# PIC32CX0525SG12084 register map
Vendor: Microchip Technology; Series: 0525SG12; File version: 0
CPU: CM4 r1p0, little endian, no MPU, no FPU, 3 interrupt priority bits, 172 interrupts
Registers are 32-bit, read-write, reset 0x0 unless marked. A register's access mark holds for its fields unless they carry their own. Offsets are from the block's base; [hi:lo] are bit positions.

## I2C0 — The I2C interface can handle standard I2C interface.
Base 0x40005100; register names take the prefix I2C_
Same registers: I2C1 0x40005200, I2C2 0x40005300
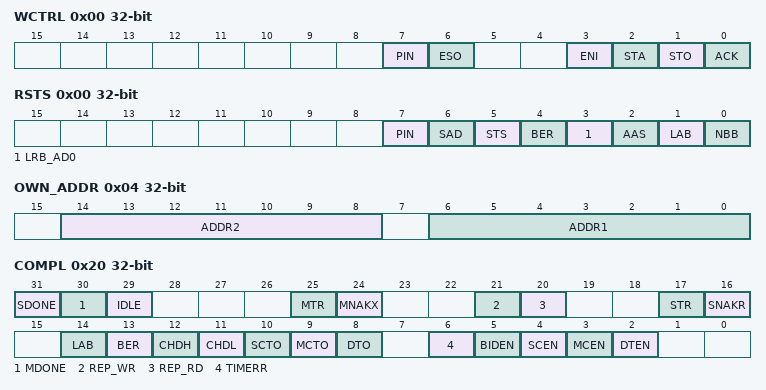
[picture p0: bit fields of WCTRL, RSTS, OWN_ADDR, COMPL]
0x00 WCTRL wo — Control Register
  [7] PIN — The Pending Interrupt Not (PIN) bit serves as a software reset function. Writing the PIN bit to a logic '1' de-asserts all status bits except for the nBB bit which is not affected by the PIN bit. The PIN bit is a self-clearing bit. Writing this bit to a logic '0' has no effect.
  [6] ESO — The Enable Serial Output bit (ESO) enables and disables the SMB Controller Core serial data output (SDAT)
  [3] ENI — Enable Interrupt bit (ENI) controls the Interrupt Interface
  [2] STA — The STA and STO bits control the generation of the I2C Start condition and the transmission of the Slave Address and R/nW bit (from the Data Register), generation of repeated Start condition, and generation of the Stop condition
  [1] STO — See STA description
  [0] ACK — The Acknowledge bit (ACK) must normally be asserted ('1'). This causes the controller to send an acknowledge automatically after each byte (this occurs during the 9th clock pulse). The ACK bit must not be asserted ('0') when the controller is operating in master/receiver mode and requires no further data to be sent from the slave transmitter. This causes a negative acknowledge on the I2C bus, which halts further transmission from the slave device.
0x00 RSTS ro — Status Register
  [7] PIN — Pending Interrupt bit
  [6] SAD — SMBus Address Decoded (SAD)
  [5] STS — When in slave receiver mode, STS is asserted ('1') when an externally generated STOP condition is detected. Note that STS is used only in slave receiver mode.
  [4] BER — When Bus Error (BER) is asserted, a misplaced START or STOP condition or Bus Time-Outs have been detected.
  [3] LRB_AD0 — The (Last Received Bit) or (Address 0) (general call) bit (LRB/AD0) serves a dual function and is valid only while the PIN bit is asserted ('0'). When the AAS bit is not asserted ('0') (i.e., not addressed as a slave), the LRB/AD0 holds the value of the last received bit over the bus. When the AAS bit is asserted ('1') (i.e., addressed as slave), the SMB Controller Core has been addressed as a slave.
  [2] AAS — The Addressed As Slave bit (AAS) is valid only when PIN is asserted ('0'). When acting as slave, AAS is set when an incoming address over the bus matches the value in the Own Address Register or if the 'general call' address (00h) has been received
  [1] LAB — The Lost Arbitration Bit (LAB) is set when, in multi-master operation, arbitration is lost to another master on the bus
  [0] NBB — The Bus Busy bit (NBB) is a read-only flag indicating when the bus is in use. A zero indicates that the bus is busy and access is not possible.
0x04 OWN_ADDR — Own Address Register. Note that the Data Register and Own Address fields are offset by one bit, so that programming Own Address 1 with a value of 55h will result in the value AAh being recognized as the SMB Controller Core slave address.
  [14:8] ADDR2 — The Own Address 2 bits configure one of the two addresses to which the SMB Controller Core will respond when addressed as a slave.
  [6:0] ADDR1 — The Own Address 1 bits configure one of the two addresses to which the SMB Controller Core will respond when addressed as a slave.
0x08 I2CDATA 8-bit — This register holds the data that are either shifted out to or shifted in from the I2C port.
0x18 RSHTM reset 0x4D — Repeated Start Hold Time Register
  [7:0] RSHTM — This is the value of the timing requirement tHd:Sta in the I2C specification for a repeated START bit. This is used to hold the clock until the Hold Time for the repeated Start Bit has been satisfied.
0x20 COMPL — Completion Register
  [31] SDONE — If this bit is 1, Slave State machine completed operation and returned to the Idle state. It is cleared when written with a 1. Writes of a 0 have no effect.(R/WC)
  [30] MDONE — If this bit is 1, Master State machine completed operation and returned to the Idle state. It is cleared when written with a 1. Writes of a 0 have no effect. (R/WC)
  [29] IDLE — This bit is set when the I2C bus becomes idle (on the rising edge of nBB). (R/WC)
  [25] MTR — 0: Master has just finished the receive phase of a transaction. 1: Master has just finished the transmit phase of a transaction.
  [24] MNAKX — If this bit is 1, the Master state machine received a NACK from the receiving Slave while the Master was transmitting data over the SMBus interface. (R/WC)
  [21] REP_WR — If this bit is 1, the Slave State Machine stopped because it detected a Repeat Start bit, with bit[0] of the byte containing the slave address equal to 0, indicating that the Master requested a Write operation.
  [20] REP_RD — If this bit is 1, the Slave State Machine stopped because it detected a Repeat Start bit, with bit[0] of the byte containing the slave address equal to 1, indicating that the Master requested a Read operation.
  [17] STR — 0: Slave has just finished the receive phase of a transaction. 1: Slave has just finished the transmit phase of a transaction.
  [16] SNAKR — If this bit is 1, the Slave state machine sent a NACK to the transmitting Master while the Slave was receiving data from the SMBus interface.
  [14] LAB — If this bit is 1, the LAB bit in the Status register was set while either the Slave state machine or the Master state machine was not in the Idle state.(R/WC)
  [13] BER — If this bit is 1, the BER bit in the Status register was set while either the Slave state machine or the Master state machine was not in the Idle state.(R/WC)
  [12] CHDH — CHDH is the bus idle time-out detect bit(R/WC)
  [11] CHDL — CHDL is the clock high time-out detect bit(R/WC)
  [10] SCTO — SCTO is the Slave Cumulative Time-out bit(R/WC)
  [9] MCTO — MCTO is the Master Cumulative Time-out bit. (R/WC)
  [8] DTO — DTO is the Device Time-out bit. (R/WC)
  [6] TIMERR — The Time-out Error Detected bit (TIMERR) is asserted ('1') whenever any of the enabled time-out error detect status bits (CHDH, CHDL, SCTO, MCTO and DTO) are asserted.
  [5] BIDEN — When BIDEN is asserted ('1'), Bus Idle Detect Time-Out checking is enabled. When BIDEN is not asserted ('0'), Bus Idle Detect Time-Out checking is disabled.
  [4] SCEN — When SCEN is asserted ('1'), Slave Cumulative Time-Out checking is enabled. When SCEN is not asserted ('0'), Slave Cumulative Time-Out checking is disabled.
  [3] MCEN — When MCEN is asserted ('1'), Master Cumulative Time-Out checking is enabled. When MCEN is not asserted ('0'), Master Cumulative Time-Out checking is disabled.
  [2] DTEN — When DTEN is asserted ('1'), Device Time-out checking is enabled. When DTEN is not asserted ('0'), Device Time-out checking is disabled.
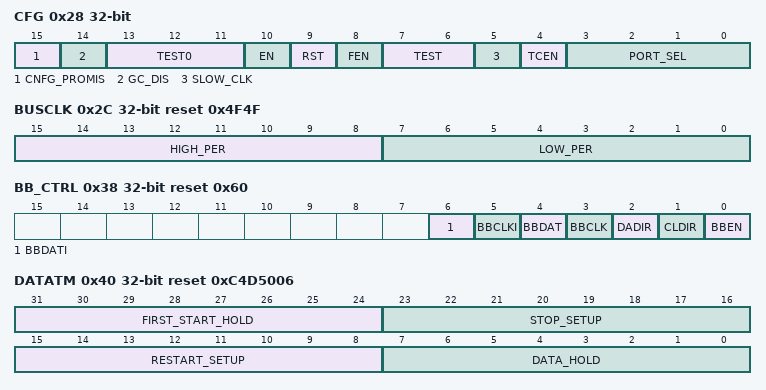
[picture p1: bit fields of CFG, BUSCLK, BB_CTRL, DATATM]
0x28 CFG — Configuration Register
  [15] CNFG_PROMIS — This is the configur Promiscuous bit. 0: Normal operation is enabled. 1: Promiscuous Mode enabled , General Call Address disabled, Promiscuous Address Interrupt function enabled. Stall 9th clock of address byte enabled. Address byte ACK/NAK done by Promiscuous ACK setting.
  [14] GC_DIS — This is the General Call Disable bit. 0: the response to the General Call address as a slave is enabled. 1: the response to the General Call address as a slave is disabled.
  [13:11] TEST0 — Must be always written with 0.
  [10] EN — When ENAB (Enable) is not asserted ('0') (default), the SMB Controller Core is disabled and in the lowest power consumption state (Disabled State). The ENAB bit must be asserted ('1') for normal operation.
  [9] RST — When RESET is asserted ('1'), all logic and registers except for the RESET bit itself are initialized to the power-on default state.
  [8] FEN — Input filtering enable. Input filtering is required by the I2C specification if external filtering is not available. 1=Input filtering is enabled; 0=Input filtering is disabled.
  [7:6] TEST — Must be always written with 0.
  [5] SLOW_CLK — When this bit is 1, the base period for the Bus Clock Register is multiplied by 4, and thus the frequency is divided by 4.
  [4] TCEN — When the Timing Check Enable bit (TCEN) is asserted ('1'), Bus Time-Outs are enabled
  [3:0] PORT_SEL — The PORT SEL [3:0] bits determine which one of 16 possible bus ports apply to the active 2-wire SDAT and SCLK bus pair.
0x2C BUSCLK reset 0x4F4F — Bus Clock Register
  [15:8] HIGH_PER — This field defines the number of I2C Baud Clock periods that make up the high phase of the I2C/SMBus bus clock.
  [7:0] LOW_PER — This field defines the number of I2C Baud Clock periods that make up the low phase of the I2C/SMBus bus clock.
0x30 BLKID 8-bit ro — Block ID Register
  [7:0] ID — Block ID.
0x34 BLKREV 8-bit ro — Revision Register
  [7:0] REV — Block Revision Number
0x38 BB_CTRL reset 0x60 — Bit-Bang Control Register
  [6] BBDATI — Bit-Bang Data In. The BBDATI bit always returns the state of SDAT
  [5] BBCLKI — Bit-Bang Clock In. The BBCLKI bit always returns the state of SCLK.
  [4] BBDAT — Bit-Bang Data. The BBDAT bit controls the state of SDAT when BBEN = and DADIR = '1'
  [3] BBCLK — Bit-Bang Clock. The BBCLK bit controls the state of SCLK when BBEN = and CLDIR = '1'
  [2] DADIR — Bit-Bang Data Direction. The DADIR bit controls the direction of SDAT. 0 - Input. 1 - Output
  [1] CLDIR — Bit-Bang Clock Direction. The CLDIR bit controls the direction of SCLK. 0 - Input, 1 - Output
  [0] BBEN — Bit-Bang Mode Enable. 0 - Bit Bang Mode Disabled. 1 - Bit Bang Mode Enabled
0x3C CLKSYNC 8-bit ro — This is Clock Sync Register. This register must not be written, or undesirable results may occur.
  [7:0] CLK_SYNC — This register must not be written, or undesirable results may occur.
0x40 DATATM reset 0xC4D5006 — Data Timing Register
  [31:24] FIRST_START_HOLD — This field determines the SCL hold time following SDA driven low during the first START bit in a transfer. It is the parameter. THD:STA in the I2C Specification for an initial START bit. Repeated START hold time is determined by the Repeated START Hold Time Register.
  [23:16] STOP_SETUP — The Stop Setup [7:0] timer determines the SDAT setup time from the rising edge of SCLK for a STOP condition.
  [15:8] RESTART_SETUP — The Restart Setup [7:0] timer determines the SDAT setup time from the rising edge of SCLK for a repeated START condition.
  [7:0] DATA_HOLD — The Data Hold [7:0] timer determines the SDAT hold time following SCLK driven low.
0x44 TMOUTSC reset 0x4B9CC2C7 — Time-Out Scaling Register
  [31:24] BUS_IDLE_MIN — Bus Idle Minimum time = Bus Idle Min [7:0] x Baud_Clock_Period
0x60 WAKE_STS — WAKE STATUS Register
  [0] START_BIT_DET — This bit is set to '1' when a START bit is detected while the controller is enabled. This bit is cleared to '0' when written with a '1'. Writes of '0' have no effect. (R/WC)
0x64 WAKE_EN — WAKE ENABLE Register
  [0] START_DET_INT_EN — Enable Start Bit Detection Interrupt. The Start Bit Detection Interrupt is wake-capable. 1=Start Bit Detection Interrupt enabled. 0=Start Bit Detection Interrupt disabled.
0x6C SLV_ADDR 8-bit — This is the Slave Address Register.
  [7:0] SADDR — This register stores the value of the Slave Address and Direction Bit from the 1st byte of a Slave transfer. This is loaded immediately upon receipt of the address byte, before the ACK/NAK 9th clock.
0x70 PRM_STS 8-bit — This is the Promiscuous Interrupt Register. This register bit will be functional only in Promiscuous mode.
  [0] ADDR_INTR — This is the Promiscuous Address Status interrupt. This bit is functional only in Promiscuous mode. This bit is set on the 8th clock of the I2C Address. This bit will hold the Clock line low till this register bit is cleared. In other words, Software should read the address program ACK/NAK and clear this bit for the ACK/NAK clock to appear on the I2C clock (SCL) line. This is Write 1 to clear. R/W1C.
0x74 PRM_IEN 8-bit — This is the Promiscuous Interrupt Enable Register.
  [0] ADDR — This is the Promiscuous interrupt enable register. 1= Interrupt Enable. 0= Interrupt Disabled.
0x78 PRM_CTRL 8-bit — This is the Promiscuous Control Register. This register is functional only in Promiscuous mode.
  [0] ACK_NAK — This is the Promiscuous ACK / NAK response register. This bit has no effect in Normal mode of operation. 1= ACK the address byte. 0= NAK the address byte.
